# $root: IP-XACT component
VLNV example.org:mylibrary:$root:1.0

## Address spaces and blocks
cr_mmap.cr: base 'h0, range 'h33f88, width 64

## Registers
Registers are 64-bit, read-write, reset 0x0 unless marked. A register's access mark holds for its fields unless they carry their own. Offsets are from the block's base; lines under a group give offsets from that group; [hi:lo] are bit positions; {n}, {i} and the like mark numbered series; 'fields as' and 'values as' point back to an identical list; <NAME> marks a mode.

## cr_mmap.cr
Base 0x00000000
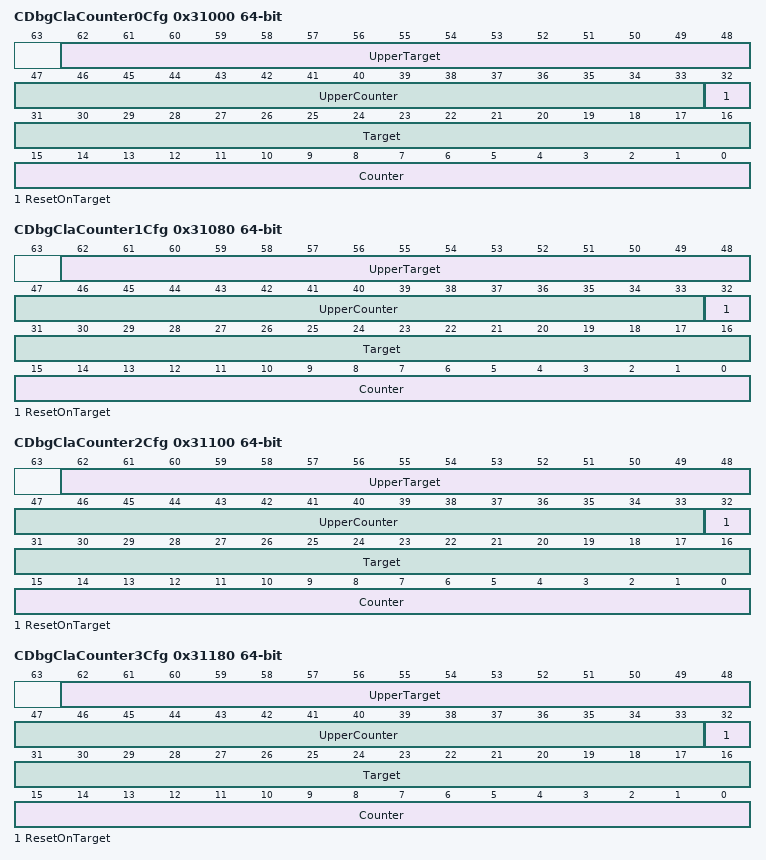
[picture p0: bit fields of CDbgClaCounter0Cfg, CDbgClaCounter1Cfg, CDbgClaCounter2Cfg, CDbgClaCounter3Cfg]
0x31000 CDbgClaCounter0Cfg — Configure CLA counter0. One of the 4 counters used for counting cycles after a event match, and trigger a action on match.
  [62:48] UpperTarget
  [47:33] UpperCounter
  [32] ResetOnTarget — When Counter = {upper_target,target} reset to 0. With this bit set, counter will provide a periodic tick w/ frequency of (target +1) if the action is set to Auto Incr. The periodic tick will continue till Stop Auto Incr or Clear Counter action.
  [31:16] Target
  [15:0] Counter
0x31080 CDbgClaCounter1Cfg — Configure CLA counter1. One of the 4 counters used for counting cycles after a event match, and trigger a action on match.
  [62:48] UpperTarget
  [47:33] UpperCounter
  [32] ResetOnTarget — When Counter = {upper_targe,target}, reset to 0. With this bit set, counter will provide a periodic tick w/ frequency of (target +1) if the action is set to Auto Incr. The periodic tick will continue till Stop Auto Incr or Clear Counter action.
  [31:16] Target
  [15:0] Counter
0x31100 CDbgClaCounter2Cfg — Configure CLA counter2. One of the 4 counters used for counting cycles after a event match, and trigger a action on match.
  [62:48] UpperTarget
  [47:33] UpperCounter
  [32] ResetOnTarget — When Counter = {upper_target,target}, reset to 0. With this bit set, counter will provide a periodic tick w/ frequency of (target +1) if the action is set to Auto Incr. The periodic tick will continue till Stop Auto Incr or Clear Counter action.
  [31:16] Target
  [15:0] Counter
0x31180 CDbgClaCounter3Cfg — Configure CLA counter3. One of the 4 counters used for counting cycles after a event match, and trigger a action on match.
  fields as CDbgClaCounter2Cfg
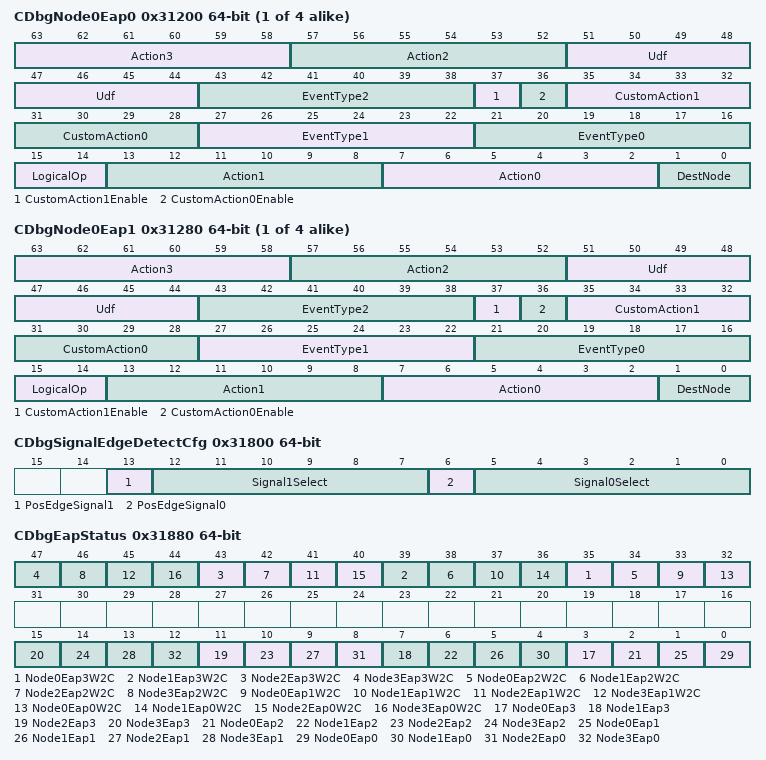
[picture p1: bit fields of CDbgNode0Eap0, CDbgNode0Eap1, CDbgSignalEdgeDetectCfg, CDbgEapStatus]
{0x31200+0x100*i} CDbgNode{i}Eap0 (i=0..3) — CLA Action(s) are tied to events(s) using "event-action pairing" registers. One of he 8 EAPs (4 EAPs per Node).
  [63:58] Action3 — Select an Action
  [57:52] Action2 — Select an Action
  [51:44] Udf — User Defined Function with event type 0, 1, and 2 as arguments
  [43:38] EventType2 — Select a trigger event
  [37] CustomAction1Enable — custom_action1 is valid only if custom_action1_enable is set
  [36] CustomAction0Enable — custom_action0 is valid only if custom_action0_enable is set
  [35:32] CustomAction1 — Select the bit position of custom action bus to be set when EAP trigger is met. External blocks can define and implement the specifc action for a given bit.
  [31:28] CustomAction0 — Select the bit position of custom action bus to be set when EAP trigger is met. External blocks can define and implement the specifc action for a given bit.
  [27:22] EventType1 — Select a trigger event
  [21:16] EventType0 — Select a trigger event
  [15:14] LogicalOp — Relation to be satisfied among events to activate the actions
  [13:8] Action1 — Select an Action
  [7:2] Action0 — Select an Action
  [1:0] DestNode — Select Destination Node
{0x31280+0x100*i} CDbgNode{i}Eap1 (i=0..3) — CLA Action(s) are tied to events(s) using "event-action pairing" registers. One of he 8 EAPs (4 EAPs per Node).
  fields as CDbgNode0Eap0
0x31600 CDbgSignalMask0 — Used to define debug bus match event. Match event (0x2) is triggered when debug_bus & mask = match.
  [63:0] Value — Mask to be applied to debug bus before match
0x31680 CDbgSignalMatch0 — Used to define debug bus match event. Match event (0x2) is triggered when debug_bus & mask = match.
  [63:0] Value — Value used for debug bus match.
0x31700 CDbgSignalMask1 — Used to define debug bus match event. Match event (0x4) is triggered when debug_bus & mask = match.
  [63:0] Value — Mask to be applied to debug bus before match
0x31780 CDbgSignalMatch1 — Used to define debug bus match event. Match event (0x4) is triggered when debug_bus & mask = match.
  [63:0] Value — Value used for debug bus match.
0x31800 CDbgSignalEdgeDetectCfg — Register to configure debug bus for edge triggers.
  [13] PosEdgeSignal1 — Defines which edge to detect for singal from signal1_select. 1: Pos edge, 0: Neg Edge
  [12:7] Signal1Select — Define which signal to select for edge detection.
  [6] PosEdgeSignal0 — Defines which edge to detect for singal from signal0_select. 1: Pos edge, 0: Neg Edge
  [5:0] Signal0Select — Define which signal to select for edge detection.
0x31880 CDbgEapStatus access per field — Register to indicate if EAP Pair was activated. Use the corresponding w2c register to reset the status. There are 2 bits for each EAP. The bit corresponds to action-0 and action-1 of the EAP. The register is used by SW to know if an action was taken (ex: NMI ISR needs to know which of the EAP triggered the NMI)
  [4n+35] Node{n}Eap3W2C rw (n=0..3), [4n+34] Node{n}Eap2W2C rw (n=0..3), [4n+33] Node{n}Eap1W2C rw (n=0..3), [4n+32] Node{n}Eap0W2C rw (n=0..3), [4n+3] Node{n}Eap3 ro (n=0..3), [4n+2] Node{n}Eap2 ro (n=0..3), [4n+1] Node{n}Eap1 ro (n=0..3), [4n] Node{n}Eap0 ro (n=0..3)
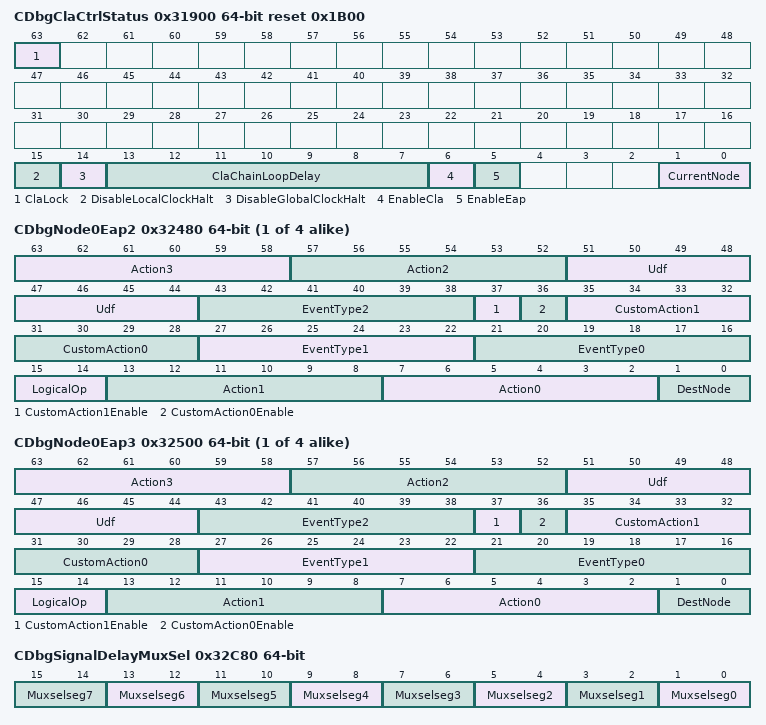
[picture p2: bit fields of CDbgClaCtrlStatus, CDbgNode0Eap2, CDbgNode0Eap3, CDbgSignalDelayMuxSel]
0x31900 CDbgClaCtrlStatus access per field reset 0x1B00 — Ctrl/Status register to Enable EAP after EAP programming is complete, and read the current node.
  [63] ClaLock rw — If this bit is set, then CLA is locked and the enbale_cla is latched forever
  [15] DisableLocalClockHalt rw — If this bit is set, clock halt action is not applied to local clocks
  [14] DisableGlobalClockHalt rw — If this bit is set, clock halt action is not applied to global clocks
  [13:7] ClaChainLoopDelay rw — Creates a window in which we don’t forward the incoming Xtrigger and Clock_Halt signal
  [6] EnableCla rw — Set this bit to 1 to enable CLA. If this bit is set, CLA is clock gated (save pwr)
  [5] EnableEap rw — Set Enable EAP to 1 after EAP programming is complete
  [1:0] CurrentNode ro — Read the current node.
{0x31980+0x80*i} CDbgRsvd{i} (i=0..2) — Reserved Register that can be changed.
  [63:0] Value — Value of reserved register.
0x31B00 CDbgTransitionMask — 3 registers to configure "transition event". This register is to select the signals of interest using a mask.
  [63:0] Value
0x31B80 CDbgTransitionFromValue — 3 registers to configure "transition event". The event is triggered on transition from Value A to Value B. This register specifies Value A.
  [63:0] Value
0x31C00 CDbgTransitionToValue — 3 registers to configure "transition event". The event is triggered on transition from Value A to Value B. This register specifies Value B.
  [63:0] Value
0x31C80 CDbgOnesCountMask — 2 registers to configure "ones count" event. This register is to select the signals of interest using a mask.
  [63:0] Value
0x31D00 CDbgOnesCountValue — 2 registers to configure "ones count" event. Event triggered when the sum of the signals match the value specified in this register.
  [63:0] Value
0x31D80 CDbgAnyChange — Event triggered when a subset of debug signals change. The mask is used to select the subset of the debug signals.
  [63:0] Mask
0x31E00 CDbgSignalSnapshotNode0Eap0 ro — debug Bus Value when Node0 Eap0 Trigger is met.
  [63:0] Value
0x31E80 CDbgSignalSnapshotNode0Eap1 ro — debug Bus Value when Node0 Eap1 Trigger is met.
  [63:0] Value
0x31F00 CDbgSignalSnapshotNode1Eap0 ro — debug Bus Value when Node1 Eap0 Trigger is met.
  [63:0] Value
0x31F80 CDbgSignalSnapshotNode1Eap1 ro — debug Bus Value when Node1 Eap0 Trigger is met.
  [63:0] Value
0x32000 CDbgSignalSnapshotNode2Eap0 ro — debug Bus Value when Node0 Eap0 Trigger is met.
  [63:0] Value
0x32080 CDbgSignalSnapshotNode2Eap1 ro — debug Bus Value when Node0 Eap1 Trigger is met.
  [63:0] Value
0x32100 CDbgSignalSnapshotNode3Eap0 ro — debug Bus Value when Node1 Eap0 Trigger is met.
  [63:0] Value
0x32180 CDbgSignalSnapshotNode3Eap1 ro — debug Bus Value when Node1 Eap0 Trigger is met.
  [63:0] Value
0x32200 CDbgClaTimeMatch — This value is compared (greater than or equal to the programmed value) against the internal time register value of the core, and is used to generate a time match event for CLA. Needs to be non zero for the time match event signal to trigger. The event will only trigger an action if the EAP programming is done. Requires writing 0 to this register to stop the match event.
  [63:0] TimeMatchVal
0x32280 CDbgSignalMask2 — Used to define debug bus match event. Match event (0x1C) is triggered when debug_bus & mask = match.
  [63:0] Value — Mask to be applied to debug bus before match
0x32300 CDbgSignalMatch2 — Used to define debug bus match event. Match event (0x1C) is triggered when debug_bus & mask = match.
  [63:0] Value — Value used for debug bus match.
0x32380 CDbgSignalMask3 — Used to define debug bus match event. Match event (0x1D) is triggered when debug_bus & mask = match.
  [63:0] Value — Mask to be applied to debug bus before match
0x32400 CDbgSignalMatch3 — Used to define debug bus match event. Match event (0x1D) is triggered when debug_bus & mask = match.
  [63:0] Value — Value used for debug bus match.
{0x32480+0x100*i} CDbgNode{i}Eap2 (i=0..3) — CLA Action(s) are tied to events(s) using "event-action pairing" registers. One of he 8 EAPs (4 EAPs per Node).
  fields as CDbgNode0Eap0
{0x32500+0x100*i} CDbgNode{i}Eap3 (i=0..3) — CLA Action(s) are tied to events(s) using "event-action pairing" registers. One of he 8 EAPs (4 EAPs per Node).
  fields as CDbgNode0Eap0
{0x32880+0x100*i} CDbgSignalSnapshotNode{i}Eap2 ro (i=0..3) — debug Bus Value when Node{i} Eap2 Trigger is met.
  [63:0] Value
{0x32900+0x100*i} CDbgSignalSnapshotNode{i}Eap3 ro (i=0..3) — debug Bus Value when Node{i} Eap3 Trigger is met.
  [63:0] Value
0x32C80 CDbgSignalDelayMuxSel
  [2n+1:2n] Muxselseg{n} (n=0..7) — Dbg Mux Shifted signals Select Bits for Lane {n}
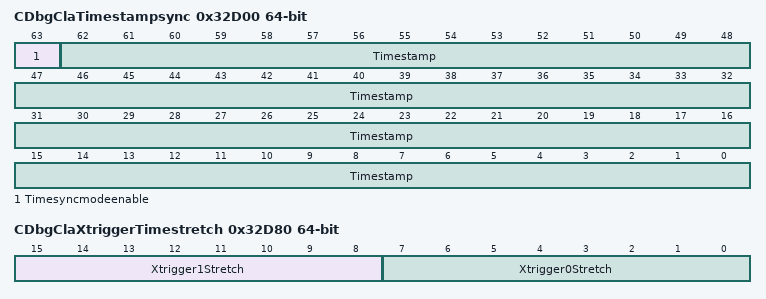
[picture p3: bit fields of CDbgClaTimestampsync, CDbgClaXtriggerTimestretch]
0x32D00 CDbgClaTimestampsync — This value is loaded to the finegrain timestamp counter based on a cross trigger to sync the time value across the multiple cluster's CLA blocks
  [63] Timesyncmodeenable, [62:0] Timestamp
0x32D80 CDbgClaXtriggerTimestretch — This value determines the time stretched pulse duration for the cross trigger. 8 bits for each of the two triggers.
  [15:8] Xtrigger1Stretch, [7:0] Xtrigger0Stretch
0x33F00 CrScratchpad reset 0xBFBFBFBFBFBFBFBF — Scratchpad register for DV
  [63:0] Data
0x33F80 Scratch — Additional scratch register for DV and potential ECO usage
  [63:0] Data
